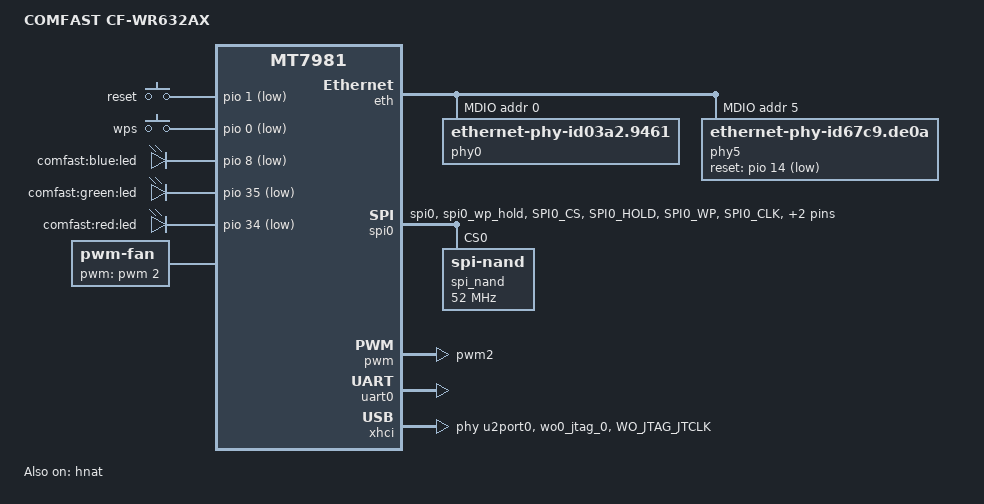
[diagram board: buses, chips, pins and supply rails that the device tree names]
// SPDX-License-Identifier: GPL-2.0-or-later OR MIT
/dts-v1/;

#include "mt7981.dtsi"

/ {
	model = "COMFAST CF-WR632AX";
	compatible = "glinet,mt3000-snand", "mediatek,mt7981";

	aliases {
		led-boot = &wifi_blue;
		led-failsafe = &wifi_blue;
		led-running = &wifi_blue;
		led-upgrade = &lan_green;
	};

	chosen {
		bootargs = "console=ttyS0,115200n1 loglevel=8 \
			    earlycon=uart8250,mmio32,0x11002000";
	};

	gpio-keys {
		compatible = "gpio-keys";

		reset {
			label = "reset";
			linux,code = <KEY_RESTART>;
			gpios = <&pio 1 GPIO_ACTIVE_LOW>;
		};

		wps {
			label = "wps";
			linux,code = <KEY_WPS_BUTTON>;
			gpios = <&pio 0 GPIO_ACTIVE_LOW>;
		};
	};

	leds {
		compatible = "gpio-leds";

		wifi_blue: wifi_blue {
			label = "comfast:blue:led";
			gpios = <&pio 8 GPIO_ACTIVE_LOW>;
		};

		lan_green: lan_green {
			label = "comfast:green:led";
			gpios = <&pio 35 GPIO_ACTIVE_LOW>;
		};

		wan_red: wan_red {
			label = "comfast:red:led";
			gpios = <&pio 34 GPIO_ACTIVE_LOW>;
		};
	};

	nmbm_spim_nand {
		compatible = "generic,nmbm";
		#address-cells = <1>;
		#size-cells = <1>;

		lower-mtd-device = <&spi_nand>;
		max-reserved-blocks = <32>;
		forced-create;

		partitions {
			compatible = "fixed-partitions";
			#address-cells = <1>;
			#size-cells = <1>;

			partition@0 {
				label = "BL2";
				reg = <0x0000000 0x0100000>;
				read-only;
			};

			partition@100000 {
				label = "u-boot-env";
				reg = <0x0100000 0x0080000>;
			};

			partition@180000 {
				label = "Factory";
				reg = <0x0180000 0x0200000>;
				read-only;
			};

			partition@380000 {
				label = "FIP";
				reg = <0x0380000 0x0200000>;
				read-only;
			};

			partition@580000 {
				label = "ubi";
				reg = <0x0580000 0x4000000>;
			};
		};
	};

	fan: pwm-fan {
		compatible = "pwm-fan";
		#cooling-cells = <2>;
		cooling-levels = <0 10 20 30 40 50 60 70 80 90 100 110 120 130 140 150 160 170 180 190 200 210 220 240 255>;
		pwms = <&pwm 2 40000 0>;
		status = "okay";
	};
};

&eth {
	status = "okay";

	gmac0: mac@0 {
		compatible = "mediatek,eth-mac";
		reg = <0>;
		phy-mode = "2500base-x";

		fixed-link {
			speed = <2500>;
			full-duplex;
			pause;
		};
	};

	gmac1: mac@1 {
                compatible = "mediatek,eth-mac";
                reg = <1>;
                phy-mode = "gmii";
                phy-handle = <&phy0>;
        };

	mdio: mdio-bus {
		#address-cells = <1>;
		#size-cells = <0>;

		phy0: phy@0 {
			compatible = "ethernet-phy-id03a2.9461";
			reg = <0>;
			nvmem-cells = <&phy_calibration>;
			nvmem-cell-names = "phy-cal-data";
		};

		phy5: phy@5 {
			compatible = "ethernet-phy-id67c9.de0a";
			reg = <5>;
			reset-gpios = <&pio 14 1>;
			reset-assert-us = <600>;
			reset-deassert-us = <20000>;
			phy-mode = "2500base-x";
		};
	};
};

&hnat {
	mtketh-wan = "eth1";
	mtketh-lan = "eth0";
	mtketh-ppd = "eth0";
	mtketh-max-gmac = <2>;
	mtketh-ppe-num = <2>;
	status = "okay";
};

&spi0 {
	pinctrl-names = "default";
	pinctrl-0 = <&spi0_flash_pins>;
	status = "okay";

	spi_nand: spi_nand@0 {
		compatible = "spi-nand";
		#address-cells = <1>;
		#size-cells = <1>;
		reg = <0>;

		spi-max-frequency = <52000000>;
		spi-tx-bus-width = <4>;
		spi-rx-bus-width = <4>;
	};
};

&pio {

	pwm2_pin: pwm2-pin {
		mux {
			function = "pwm";
			groups = "pwm2";
		};
	};

	usb_pwr_pins: usb-pins {
		mux {
			function = "jtag";
			groups = "wo0_jtag_0";
		};

		power {
			pins = "WO_JTAG_JTCLK";
			drive-strength = <MTK_DRIVE_8mA>;
			mediatek,pull-up-adv = <1>;
		};
	};

	spi0_flash_pins: spi0-pins {
		mux {
			function = "spi";
			groups = "spi0", "spi0_wp_hold";
		};

		conf-pu {
			pins = "SPI0_CS", "SPI0_HOLD", "SPI0_WP";
			drive-strength = <MTK_DRIVE_8mA>;
			bias-pull-up = <MTK_PUPD_SET_R1R0_11>;
		};

		conf-pd {
			pins = "SPI0_CLK", "SPI0_MOSI", "SPI0_MISO";
			drive-strength = <MTK_DRIVE_8mA>;
			bias-pull-down = <MTK_PUPD_SET_R1R0_11>;
		};
	};
};

&pwm {
	pinctrl-names = "default";
	pinctrl-0 = <&pwm2_pin>;
	status = "okay";
};

&uart0 {
	status = "okay";
};

&xhci {
	mediatek,u3p-dis-msk = <0x0>;
	phys = <&u2port0 PHY_TYPE_USB2>,
	       <&u3port0 PHY_TYPE_USB3>;
	pinctrl-0 = <&usb_pwr_pins>;
	pinctrl-names = "default";
	status = "okay";
};
